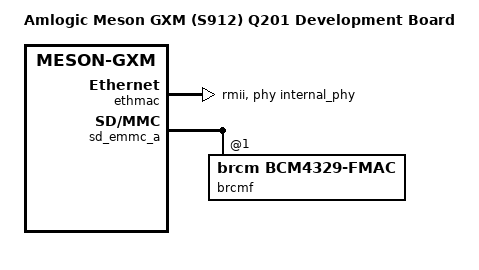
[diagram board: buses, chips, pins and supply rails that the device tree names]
/dts-v1/;
#include "meson-gxm.dtsi"
#include "meson-gx-p23x-q20x.dtsi"
/ {
	compatible = "amlogic,q201", "amlogic,s912", "amlogic,meson-gxm";
	model = "Amlogic Meson GXM (S912) Q201 Development Board";
};
&ethmac {
	phy-mode = "rmii";
	phy-handle = <&internal_phy>;
};
&sd_emmc_a {
	brcmf: wifi@1 {
		reg = <1>;
		compatible = "brcm,bcm4329-fmac";
	};
};
